# MCXN947_cm33_core0 register map
Vendor: nxp.com; File version: 1.0
CPU: CM33 r2p0, little endian, MPU, FPU, VTOR, 3 interrupt priority bits
Registers are 32-bit, read-write, reset 0x0 unless marked. A register's access mark holds for its fields unless they carry their own. Offsets are from the block's base; [hi:lo] are bit positions; {n}, {i} and the like mark numbered series; 'fields as' and 'values as' point back to an identical list.

## GPIO0 — GPIO
Base 0x40096000
Same registers: GPIO5 0x40040000, GPIO5_ALIAS1 0x40041000, GPIO0_ALIAS1 0x40097000, GPIO1 0x40098000, GPIO1_ALIAS1 0x40099000, GPIO2 0x4009A000, GPIO2_ALIAS1 0x4009B000, GPIO3 0x4009C000, GPIO3_ALIAS1 0x4009D000, GPIO4 0x4009E000, GPIO4_ALIAS1 0x4009F000
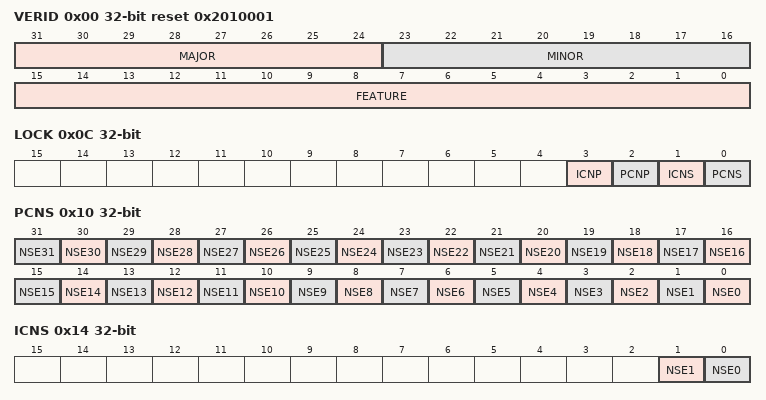
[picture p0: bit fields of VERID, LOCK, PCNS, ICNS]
0x00 VERID ro reset 0x2010001 — Version ID
  [31:24] MAJOR — Major Version Number
  [23:16] MINOR — Minor Version Number
  [15:0] FEATURE — Feature Specification Number
    0=Basic implementation; 1=Protection registers implemented
0x04 PARAM ro reset 0x2 — Parameter
  [3:0] IRQNUM — Interrupt Number
0x0C LOCK
  [3] ICNP — Lock ICNP
    0=ICNP register is writable by software in Secure-Privilege state; 1=ICNP register is not writable until the next reset
  [2] PCNP — Lock PCNP
    0=PCNP register is writable by software in Secure-Privilege state; 1=PCNP register is not writable until the next reset
  [1] ICNS — Lock ICNS
    0=ICNS register is writable by software in Secure-Privilege state; 1=ICNS register is not writable until the next reset
  [0] PCNS — Lock PCNS
    0=PCNS register is writable by software in Secure-Privilege state; 1=PCNS register is not writable until the next reset
0x10 PCNS — Pin Control Non-Secure
  [all] fields
    0=nse0 (The pin is configured for Secure access. Read or write access to the corresponding pin's registers and bit fields is only allowed by software in Secure state. When the corresponding pin's registers are accessed by software in Non-Secure state, all bits in the registers related to that pin are read zero and write ignored.); 1=nse1 (The pin is configured for Non-Secure access. Read or write access to the corresponding pin's registers and bit fields is only allowed by software in Non-Secure state. When the corresponding pin's registers are accessed by software in Secure state, all bits in the registers related to that pin are read zero and write ignored.)
  [n] NSE{n} (n=0..31) — Non-Secure Enable
0x14 ICNS — Interrupt Control Non-Secure
  [1] NSE1 — Non-Secure Enable
    0=nse0 (The interrupt, output trigger or DMA request is configured for Secure access. Only software in Secure state can configure a pin to use the corresponding interrupt, output trigger or DMA request or reconfigure a pin that is already configured to use the corresponding interrupt, output trigger or DMA request.); 1=nse1 (The interrupt, output trigger or DMA request is configured for Non-Secure access. Only software in Non-Secure state can configure a pin to use the corresponding interrupt, output trigger or DMA request or reconfigure a pin that is already configured to use the corresponding interrupt, output trigger or DMA request.)
  [0] NSE0 — Non-Secure Enable
    values as NSE1
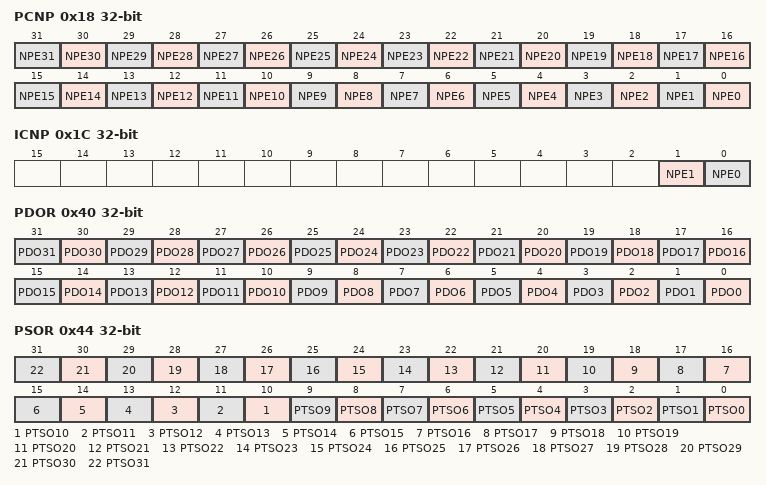
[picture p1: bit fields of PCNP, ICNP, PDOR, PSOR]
0x18 PCNP — Pin Control Non-Privilege
  [all] fields
    0=npe0 (The pin is configured for Privilege access. Write access to the corresponding pin's registers and bit fields is allowed only by software in Privilege state. When the corresponding pin's registers and bit fields are accessed by software in Non-Privilege state, all bits related to that pin in this GPIO are readable but write ignored.); 1=npe1 (The pin is configured for Non-Privilege access, Read or write access to the corresponding pin's registers is allowed by software in both Privilege and Non-Privilege state.)
  [n] NPE{n} (n=0..31) — Non-Privilege Enable
0x1C ICNP — Interrupt Control Non-Privilege
  [1] NPE1 — Non-Privilege Enable
    0=npe0 (The pin is configured for Privilege access. Only software in Privilege state can configure a pin to use the corresponding interrupt/trigger output/DMA request or reconfigure a pin that is already configured to use the corresponding interrupt/trigger output/DMA request.); 1=npe1 (The pin is configured for Non-Privilege access. Software in either Privilege or Non-Privilege state can configure a pin to use the corresponding interrupt/trigger output/DMA request or reconfigure a pin that is already configured to use the corresponding interrupt/trigger output/DMA request.)
  [0] NPE0 — Non-Privilege Enable
    values as NPE1
0x40 PDOR — Port Data Output Register
  [all] fields
    0=pdo0 (Logic level 0 is driven on pin, if the pin is configured for general-purpose output.); 1=pdo1 (Logic level 1 is driven on pin, if the pin is configured for general-purpose output.)
  [n] PDO{n} (n=0..31) — Port Data Output
0x44 PSOR — Port Set Output Register
  [all] fields
    0=ptso0 (Corresponding field of PDOR[PDOn] does not change.); 1=ptso1 (Corresponding field of PDOR[PDOn] is set to logic 1.)
  [n] PTSO{n} (n=0..31) — Port Set Output
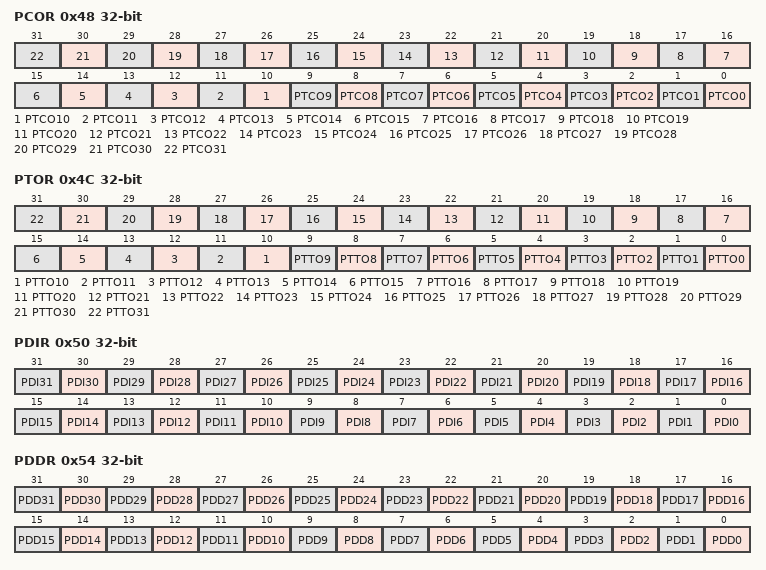
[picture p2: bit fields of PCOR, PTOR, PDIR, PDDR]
0x48 PCOR — Port Clear Output Register
  [all] fields
    0=ptco0 (Corresponding field of PDOR[PDOn] does not change.); 1=ptco1 (Corresponding field of PDOR[PDOn] is cleared to logic 0.)
  [n] PTCO{n} (n=0..31) — Port Clear Output
0x4C PTOR — Port Toggle Output Register
  [all] fields
    0=ptto0 (Corresponding field of PDOR[PDOn] does not change.); 1=ptto1 (Corresponding field of PDOR[PDOn] is set to the inverse of its current logic state.)
  [n] PTTO{n} (n=0..31) — Port Toggle Output
0x50 PDIR ro — Port Data Input Register
  [all] fields
    0=pdi0 (Pin logic level is logic 0 or is not configured for use by digital function.); 1=pdi1 (Pin logic level is logic 1.)
  [n] PDI{n} (n=0..31) — Port Data Input
0x54 PDDR — Port Data Direction Register
  [all] fields
    0=pdd0 (Pin is configured as general-purpose input for the GPIO function.); 1=pdd1 (Pin is configured as general-purpose output for the GPIO function.)
  [n] PDD{n} (n=0..31) — Port Data Direction
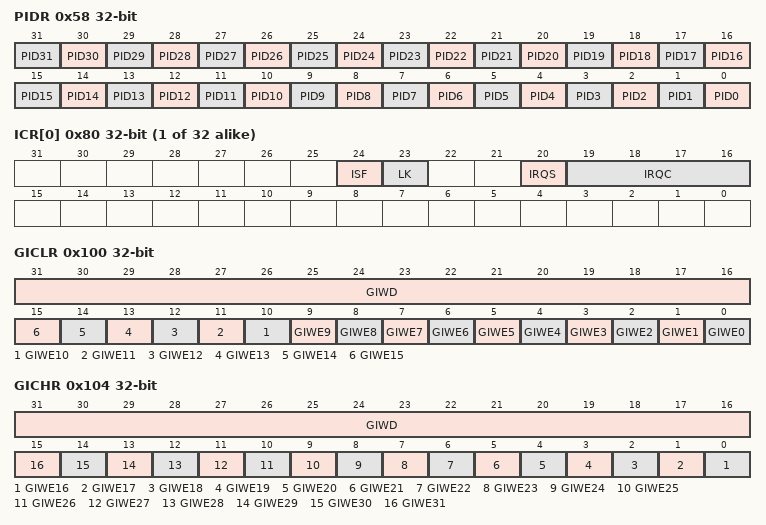
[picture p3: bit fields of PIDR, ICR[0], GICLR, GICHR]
0x58 PIDR — Port Input Disable Register
  [all] fields
    0=pid0 (Pin is configured for general-purpose input provided, the pin is configured for any digital function.); 1=pid1 (Pin is disabled for general-purpose input.)
  [n] PID{n} (n=0..31) — Port Input Disable
{0x60+i} PDR[{i}] (i=0..31) 8-bit — Pin Data Register a
  [0] PD — Pin Data (input and output)
    0=Pin logic level is logic zero or not configured for use by digital function; 1=Pin logic level is logic one
{0x80+4i} ICR[{i}] (i=0..31) — Interrupt Control Register index
  [24] ISF write-1-clears — Interrupt Status Flag
    0=Configured interrupt is not detected; 1=Configured interrupt is detected. If the pin is configured to generate a DMA request, then the corresponding flag will be cleared automatically at the completion of the requested DMA transfer. Otherwise, the flag remains set until a logic 1 is written to the flag. If the pin is configured for a level sensitive interrupt and the pin remains asserted, then the flag is set again immediately after it is cleared.
  [23] LK — Lock Register
    0=Interrupt configuration by ICR[23:0] is not locked and can be updated; 1=Interrupt configuration by ICR[23:0] is locked and cannot be updated until next system reset
  [20] IRQS — Interrupt Select
    0=Interrupt/trigger output/DMA request 0; 1=Interrupt/trigger output/DMA request 1
  [19:16] IRQC — Interrupt Configuration
    0=Interrupt Status Flag (ISF) is disabled; 1=ISF flag and DMA request on rising edge; 2=ISF flag and DMA request on falling edge; 3=ISF flag and DMA request on either edge; 5=ISF flag sets on rising edge; 6=ISF flag sets on falling edge; 7=ISF flag sets on either edge; 8=ISF flag and Interrupt when logic 0; 9=ISF flag and Interrupt on rising-edge; 10=ISF flag and Interrupt on falling-edge; 11=ISF flag and Interrupt on either edge; 12=ISF flag and Interrupt when logic 1; 13=Enable active high trigger output, ISF flag on rising edge. Pin state is ORed with other enabled triggers to generate the output trigger, for use by other peripherals.; 14=Enable active low trigger output, ISF flag on falling edge. Pin state is inverted and ORed with other enabled triggers to generate the output trigger, for use by other peripherals.
0x100 GICLR — Global Interrupt Control Low Register
  [31:16] GIWD — Global Interrupt Write Data
  [n] GIWE{n} (n=0..15) — Global Interrupt Write Enable
    0=giwe0 (Upper 16-bit of corresponding Interrupt Control Register is not updated with the value in GIWD.); 1=giwe1 (Upper 16-bit of corresponding Interrupt Control Register is updated with the value in GIWD.)
0x104 GICHR — Global Interrupt Control High Register
  [31:16] GIWD — Global Interrupt Write Data
  [n-16] GIWE{n} (n=16..31) — Global Interrupt Write Enable
    values as GICLR.GIWE0
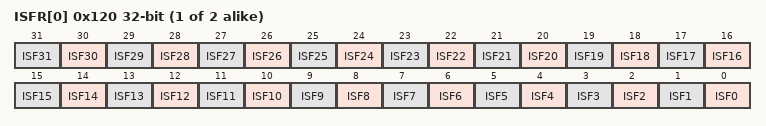
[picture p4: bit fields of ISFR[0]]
{0x120+4i} ISFR[{i}] (i=0..1) write-1-clears — Interrupt Status Flag Register
  [all] fields
    0=isf0 (Configured interrupt is not detected on the pin of the same number.); 1=isf1 (Configured interrupt is detected on the pin of the same number. If the pin is configured to generate a DMA request, then the corresponding flag will be cleared automatically at the completion of the requested DMA transfer. Otherwise, the flag remains set until a logic 1 is written to the flag. If the pin is configured for a level sensitive interrupt and the pin remains asserted, then the flag is set again immediately after it is cleared.)
  [n] ISF{n} write-1-clears (n=0..31) — Interrupt Status Flag
